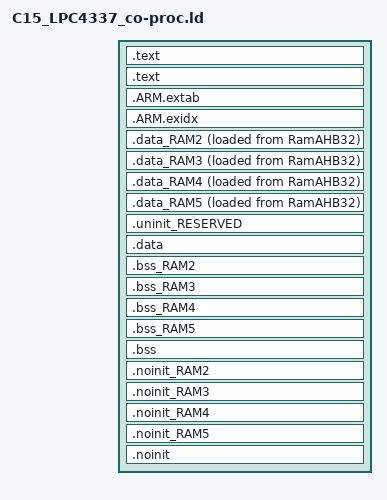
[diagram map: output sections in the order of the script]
INCLUDE "C15_LPC4337_co-proc_MEM.ld"

ENTRY(ResetISR)

SECTIONS
{
    /* MAIN TEXT SECTION */
    .text : ALIGN(4)
    {
        FILL(0xff)
        __vectors_start__ = ABSOLUTE(.) ;
        KEEP(*(.isr_vector))
        /* Global Section Table */
        . = ALIGN(4) ; 
        __section_table_start = .;
        __data_section_table = .;
        LONG(LOADADDR(.data));
        LONG(    ADDR(.data));
        LONG(  SIZEOF(.data));
        LONG(LOADADDR(.data_RAM2));
        LONG(    ADDR(.data_RAM2));
        LONG(  SIZEOF(.data_RAM2));
        LONG(LOADADDR(.data_RAM3));
        LONG(    ADDR(.data_RAM3));
        LONG(  SIZEOF(.data_RAM3));
        LONG(LOADADDR(.data_RAM4));
        LONG(    ADDR(.data_RAM4));
        LONG(  SIZEOF(.data_RAM4));
        LONG(LOADADDR(.data_RAM5));
        LONG(    ADDR(.data_RAM5));
        LONG(  SIZEOF(.data_RAM5));
        __data_section_table_end = .;
        __bss_section_table = .;
        LONG(    ADDR(.bss));
        LONG(  SIZEOF(.bss));
        LONG(    ADDR(.bss_RAM2));
        LONG(  SIZEOF(.bss_RAM2));
        LONG(    ADDR(.bss_RAM3));
        LONG(  SIZEOF(.bss_RAM3));
        LONG(    ADDR(.bss_RAM4));
        LONG(  SIZEOF(.bss_RAM4));
        LONG(    ADDR(.bss_RAM5));
        LONG(  SIZEOF(.bss_RAM5));
        __bss_section_table_end = .;
        __section_table_end = . ;
	    /* End of Global Section Table */

        *(.after_vectors*)

    } >RamAHB32

    .text : ALIGN(4)    
    {
        *(.text*)
        *(.rodata .rodata.* .constdata .constdata.*)
        . = ALIGN(4);
    } > RamAHB32
    /*
     * for exception handling/unwind - some Newlib functions (in common
     * with C++ and STDC++) use this. 
     */
    .ARM.extab : ALIGN(4) 
    {
        *(.ARM.extab* .gnu.linkonce.armextab.*)
    } > RamAHB32
    __exidx_start = .;

    .ARM.exidx : ALIGN(4)
    {
        *(.ARM.exidx* .gnu.linkonce.armexidx.*)
    } > RamAHB32
    __exidx_end = .;

    _etext = .;
        
    /* DATA section for RamLoc40 */
    .data_RAM2 : ALIGN(4)
    {
        FILL(0xff)
        PROVIDE(__start_data_RAM2 = .) ;
        *(.ramfunc.$RAM2)
        *(.ramfunc.$RamLoc40)
        *(.data.$RAM2*)
        *(.data.$RamLoc40*)
        . = ALIGN(4) ;
        PROVIDE(__end_data_RAM2 = .) ;
     } > RamLoc40 AT>RamAHB32

    /* DATA section for RamAHB16 */
    .data_RAM3 : ALIGN(4)
    {
        FILL(0xff)
        PROVIDE(__start_data_RAM3 = .) ;
        *(.ramfunc.$RAM3)
        *(.ramfunc.$RamAHB16)
        *(.data.$RAM3*)
        *(.data.$RamAHB16*)
        . = ALIGN(4) ;
        PROVIDE(__end_data_RAM3 = .) ;
     } > RamAHB16 AT>RamAHB32

    /* DATA section for RamLoc32 */
    .data_RAM4 : ALIGN(4)
    {
        FILL(0xff)
        PROVIDE(__start_data_RAM4 = .) ;
        *(.ramfunc.$RAM4)
        *(.ramfunc.$RamLoc32)
        *(.data.$RAM4*)
        *(.data.$RamLoc32*)
        . = ALIGN(4) ;
        PROVIDE(__end_data_RAM4 = .) ;
     } > RamLoc32 AT>RamAHB32

    /* DATA section for RamAHB_ETB16 */
    .data_RAM5 : ALIGN(4)
    {
        FILL(0xff)
        PROVIDE(__start_data_RAM5 = .) ;
        *(.ramfunc.$RAM5)
        *(.ramfunc.$RamAHB_ETB16)
        *(.data.$RAM5*)
        *(.data.$RamAHB_ETB16*)
        . = ALIGN(4) ;
        PROVIDE(__end_data_RAM5 = .) ;
     } > RamAHB_ETB16 AT>RamAHB32

    /* MAIN DATA SECTION */
    .uninit_RESERVED : ALIGN(4)
    {
        KEEP(*(.bss.$RESERVED*))
        . = ALIGN(4) ;
        _end_uninit_RESERVED = .;
    } > RamAHB32
    /* Main DATA section (RamAHB32) */
    .data : ALIGN(4)
    {
       FILL(0xff)
       _data = . ;
       *(vtable)
       *(.ramfunc*)
       *(.data*)
       . = ALIGN(4) ;
       _edata = . ;
    } > RamAHB32 AT>RamAHB32
    /* BSS section for RamLoc40 */
    .bss_RAM2 : ALIGN(4)
    {
       PROVIDE(__start_bss_RAM2 = .) ;
       *(.bss.$RAM2*)
       *(.bss.$RamLoc40*)
       . = ALIGN (. != 0 ? 4 : 1) ; /* avoid empty segment */
       PROVIDE(__end_bss_RAM2 = .) ;
    } > RamLoc40 
    /* BSS section for RamAHB16 */
    .bss_RAM3 : ALIGN(4)
    {
       PROVIDE(__start_bss_RAM3 = .) ;
       *(.bss.$RAM3*)
       *(.bss.$RamAHB16*)
       . = ALIGN (. != 0 ? 4 : 1) ; /* avoid empty segment */
       PROVIDE(__end_bss_RAM3 = .) ;
    } > RamAHB16 
    /* BSS section for RamLoc32 */
    .bss_RAM4 : ALIGN(4)
    {
       PROVIDE(__start_bss_RAM4 = .) ;
       *(.bss.$RAM4*)
       *(.bss.$RamLoc32*)
       . = ALIGN (. != 0 ? 4 : 1) ; /* avoid empty segment */
       PROVIDE(__end_bss_RAM4 = .) ;
    } > RamLoc32 
    /* BSS section for RamAHB_ETB16 */
    .bss_RAM5 : ALIGN(4)
    {
       PROVIDE(__start_bss_RAM5 = .) ;
       *(.bss.$RAM5*)
       *(.bss.$RamAHB_ETB16*)
       . = ALIGN (. != 0 ? 4 : 1) ; /* avoid empty segment */
       PROVIDE(__end_bss_RAM5 = .) ;
    } > RamAHB_ETB16 
    /* MAIN BSS SECTION */
    .bss : ALIGN(4)
    {
        _bss = .;
        *(.bss*)
        *(COMMON)
        . = ALIGN(4) ;
        _ebss = .;
        PROVIDE(end = .);
    } > RamAHB32
    /* NOINIT section for RamLoc40 */
    .noinit_RAM2 (NOLOAD) : ALIGN(4)
    {
       *(.noinit.$RAM2*)
       *(.noinit.$RamLoc40*)
       . = ALIGN(4) ;
    } > RamLoc40 
    /* NOINIT section for RamAHB16 */
    .noinit_RAM3 (NOLOAD) : ALIGN(4)
    {
       *(.noinit.$RAM3*)
       *(.noinit.$RamAHB16*)
       . = ALIGN(4) ;
    } > RamAHB16 
    /* NOINIT section for RamLoc32 */
    .noinit_RAM4 (NOLOAD) : ALIGN(4)
    {
       *(.noinit.$RAM4*)
       *(.noinit.$RamLoc32*)
       . = ALIGN(4) ;
    } > RamLoc32 
    /* NOINIT section for RamAHB_ETB16 */
    .noinit_RAM5 (NOLOAD) : ALIGN(4)
    {
       *(.noinit.$RAM5*)
       *(.noinit.$RamAHB_ETB16*)
       . = ALIGN(4) ;
    } > RamAHB_ETB16 
    /* DEFAULT NOINIT SECTION */
    .noinit (NOLOAD): ALIGN(4)
    {
        _noinit = .;
        *(.noinit*) 
         . = ALIGN(4) ;
        _end_noinit = .;
    } > RamAHB32

/*    PROVIDE(_pvHeapStart = DEFINED(__user_heap_base) ? __user_heap_base : .); */
/*    PROVIDE(_vStackTop = DEFINED(__user_stack_top) ? __user_stack_top : __top_RamAHB32 - 0); */
    PROVIDE(_vStackTop = __top_RamAHB32 - 0);
}
